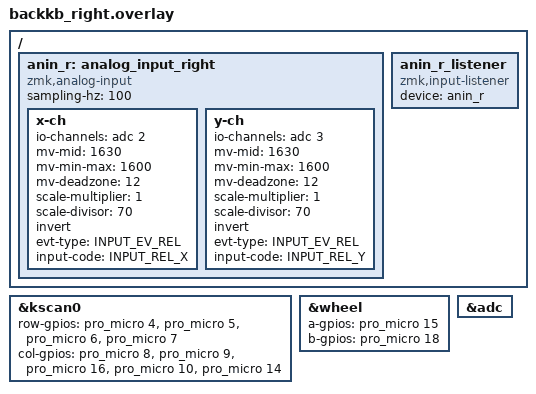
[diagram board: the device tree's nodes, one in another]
#include "backkb.dtsi"

&kscan0 {
    row-gpios
        = <&pro_micro 4  (GPIO_ACTIVE_HIGH | GPIO_PULL_DOWN)>
        , <&pro_micro 5  (GPIO_ACTIVE_HIGH | GPIO_PULL_DOWN)>
        , <&pro_micro 6  (GPIO_ACTIVE_HIGH | GPIO_PULL_DOWN)>
        , <&pro_micro 7  (GPIO_ACTIVE_HIGH | GPIO_PULL_DOWN)>
        ;
    col-gpios
        = <&pro_micro 8  GPIO_ACTIVE_HIGH>
        , <&pro_micro 9  GPIO_ACTIVE_HIGH>
        , <&pro_micro 16 GPIO_ACTIVE_HIGH>
        , <&pro_micro 10 GPIO_ACTIVE_HIGH>
        , <&pro_micro 14 GPIO_ACTIVE_HIGH>
        ;
};

&wheel {
    status = "okay";
    a-gpios = <&pro_micro 15 (GPIO_ACTIVE_HIGH | GPIO_PULL_UP)>;
    b-gpios = <&pro_micro 18 (GPIO_ACTIVE_HIGH | GPIO_PULL_UP)>;
};

&adc { status = "okay"; };

/ {
    anin_r: analog_input_right {
        compatible = "zmk,analog-input";
        sampling-hz = <100>;
        x-ch {
            io-channels = <&adc 2>;
            mv-mid = <1630>;
            mv-min-max = <1600>;
            mv-deadzone = <12>;
            scale-multiplier = <1>;
            scale-divisor = <70>;
            invert;
            evt-type = <INPUT_EV_REL>;
            input-code = <INPUT_REL_X>;
        };
        y-ch {
            io-channels = <&adc 3>;
            mv-mid = <1630>;
            mv-min-max = <1600>;
            mv-deadzone = <12>;
            scale-multiplier = <1>;
            scale-divisor = <70>;
            invert;
            evt-type = <INPUT_EV_REL>;
            input-code = <INPUT_REL_Y>;
        };
    };

    anin_r_listener: anin_r_listener {
        compatible = "zmk,input-listener";
        device = <&anin_r>;
    };
};
